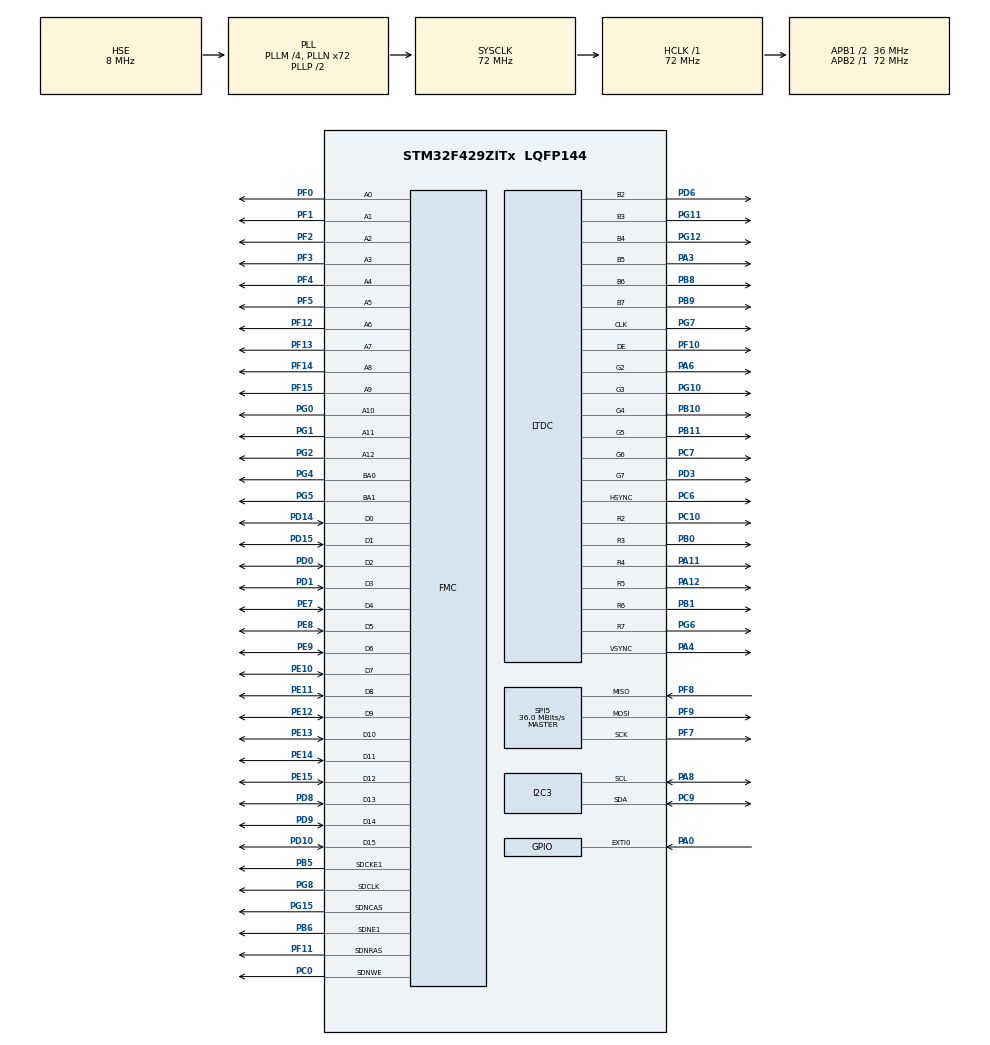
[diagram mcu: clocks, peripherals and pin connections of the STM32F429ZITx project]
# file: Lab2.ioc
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FREERTOS.INCLUDE_vTaskDelayUntil=1
FREERTOS.Queues01=myQueue01,50,uint8_t,0,Dynamic,NULL,NULL
FREERTOS.Tasks01=defaultTask,0,128,StartDefaultTask,Default,NULL,Dynamic,NULL,NULL
FREERTOS.configUSE_NEWLIB_REENTRANT=1
Mcu.Family=STM32F4
Mcu.Name=STM32F429ZITx
Mcu.Package=LQFP144
NVIC.EXTI0_IRQn=true\:5\:0\:false\:false\:true\:false\:true\:true\:true
NVIC.PriorityGroup=NVIC_PRIORITYGROUP_4
NVIC.TIM1_UP_TIM10_IRQn=true\:15\:0\:false\:false\:true\:false\:false\:true\:true
NVIC.TimeBase=TIM1_UP_TIM10_IRQn
NVIC.TimeBaseIP=TIM1
PA0/WKUP.Signal=GPXTI0
PA11.Mode=RGB666
PA11.Signal=LTDC_R4
PA12.Mode=RGB666
PA12.Signal=LTDC_R5
PA13.Mode=Serial_Wire
PA13.Signal=SYS_JTMS-SWDIO
PA14.Mode=Serial_Wire
PA14.Signal=SYS_JTCK-SWCLK
PA3.Mode=RGB666
PA3.Signal=LTDC_B5
PA4.Mode=RGB666
PA4.Signal=LTDC_VSYNC
PA6.Mode=RGB666
PA6.Signal=LTDC_G2
PA8.Mode=I2C
PA8.Signal=I2C3_SCL
PB0.Mode=RGB666
PB0.Signal=LTDC_R3
PB1.Mode=RGB666
PB1.Signal=LTDC_R6
PB10.Mode=RGB666
PB10.Signal=LTDC_G4
PB11.Mode=RGB666
PB11.Signal=LTDC_G5
PB5.Mode=SdramChipSelect2_1
PB5.Signal=FMC_SDCKE1
PB6.Mode=SdramChipSelect2_1
PB6.Signal=FMC_SDNE1
PB8.Mode=RGB666
PB8.Signal=LTDC_B6
PB9.Mode=RGB666
PB9.Signal=LTDC_B7
PC0.Signal=FMC_SDNWE
PC10.Mode=RGB666
PC10.Signal=LTDC_R2
PC6.Mode=RGB666
PC6.Signal=LTDC_HSYNC
PC7.Mode=RGB666
PC7.Signal=LTDC_G6
PC9.Mode=I2C
PC9.Signal=I2C3_SDA
PD0.Signal=FMC_D2_DA2
PD1.Signal=FMC_D3_DA3
PD10.Signal=FMC_D15_DA15
PD14.Signal=FMC_D0_DA0
PD15.Signal=FMC_D1_DA1
PD3.Mode=RGB666
PD3.Signal=LTDC_G7
PD6.Mode=RGB666
PD6.Signal=LTDC_B2
PD8.Signal=FMC_D13_DA13
PD9.Signal=FMC_D14_DA14
PE10.Signal=FMC_D7_DA7
PE11.Signal=FMC_D8_DA8
PE12.Signal=FMC_D9_DA9
PE13.Signal=FMC_D10_DA10
PE14.Signal=FMC_D11_DA11
PE15.Signal=FMC_D12_DA12
PE7.Signal=FMC_D4_DA4
PE8.Signal=FMC_D5_DA5
PE9.Signal=FMC_D6_DA6
PF0.Signal=FMC_A0
PF1.Signal=FMC_A1
PF10.Mode=RGB666
PF10.Signal=LTDC_DE
PF11.Signal=FMC_SDNRAS
PF12.Signal=FMC_A6
PF13.Signal=FMC_A7
PF14.Signal=FMC_A8
PF15.Signal=FMC_A9
PF2.Signal=FMC_A2
PF3.Signal=FMC_A3
PF4.Signal=FMC_A4
PF5.Signal=FMC_A5
PF7.Mode=Full_Duplex_Master
PF7.Signal=SPI5_SCK
PF8.Mode=Full_Duplex_Master
PF8.Signal=SPI5_MISO
PF9.Mode=Full_Duplex_Master
PF9.Signal=SPI5_MOSI
PG0.Signal=FMC_A10
PG1.Signal=FMC_A11
PG10.Mode=RGB666
PG10.Signal=LTDC_G3
PG11.Mode=RGB666
PG11.Signal=LTDC_B3
PG12.Mode=RGB666
PG12.Signal=LTDC_B4
PG15.Signal=FMC_SDNCAS
PG2.Signal=FMC_A12
PG4.Signal=FMC_A14_BA0
PG5.Signal=FMC_A15_BA1
PG6.Mode=RGB666
PG6.Signal=LTDC_R7
PG7.Mode=RGB666
PG7.Signal=LTDC_CLK
PG8.Signal=FMC_SDCLK
PH0/OSC_IN.Mode=HSE-External-Oscillator
PH0/OSC_IN.Signal=RCC_OSC_IN
PH1/OSC_OUT.Mode=HSE-External-Oscillator
PH1/OSC_OUT.Signal=RCC_OSC_OUT
ProjectManager.HeapSize=0x200
ProjectManager.StackSize=0x400
ProjectManager.TargetToolchain=STM32CubeIDE
RCC.48MHZClocksFreq_Value=48000000
RCC.AHBFreq_Value=72000000
RCC.APB1CLKDivider=RCC_HCLK_DIV2
RCC.APB1Freq_Value=36000000
RCC.APB1TimFreq_Value=72000000
RCC.APB2Freq_Value=72000000
RCC.APB2TimFreq_Value=72000000
RCC.CortexFreq_Value=72000000
RCC.HCLKFreq_Value=72000000
RCC.HSE_VALUE=8000000
RCC.HSI_VALUE=16000000
RCC.LSE_VALUE=32768
RCC.PLLM=4
RCC.PLLN=72
RCC.PLLQ=3
RCC.PLLSAIDivR=RCC_PLLSAIDIVR_4
RCC.PLLSAIN=50
RCC.PLLSAIR=5
RCC.PLLSourceVirtual=RCC_PLLSOURCE_HSE
RCC.SYSCLKFreq_VALUE=72000000
RCC.SYSCLKSource=RCC_SYSCLKSOURCE_PLLCLK
RCC.VCOOutputFreq_Value=144000000
SH.FMC_A0.0=FMC_A0,13b-sda1
SH.FMC_A1.0=FMC_A1,13b-sda1
SH.FMC_A10.0=FMC_A10,13b-sda1
SH.FMC_A11.0=FMC_A11,13b-sda1
SH.FMC_A12.0=FMC_A12,13b-sda1
SH.FMC_A14_BA0.0=FMC_BA0,FourSdramBanks1
SH.FMC_A15_BA1.0=FMC_BA1,FourSdramBanks1
SH.FMC_A2.0=FMC_A2,13b-sda1
SH.FMC_A3.0=FMC_A3,13b-sda1
SH.FMC_A4.0=FMC_A4,13b-sda1
SH.FMC_A5.0=FMC_A5,13b-sda1
SH.FMC_A6.0=FMC_A6,13b-sda1
SH.FMC_A7.0=FMC_A7,13b-sda1
SH.FMC_A8.0=FMC_A8,13b-sda1
SH.FMC_A9.0=FMC_A9,13b-sda1
SH.FMC_D0_DA0.0=FMC_D0,sd-16b-d1
SH.FMC_D10_DA10.0=FMC_D10,sd-16b-d1
SH.FMC_D11_DA11.0=FMC_D11,sd-16b-d1
SH.FMC_D12_DA12.0=FMC_D12,sd-16b-d1
SH.FMC_D13_DA13.0=FMC_D13,sd-16b-d1
SH.FMC_D14_DA14.0=FMC_D14,sd-16b-d1
SH.FMC_D15_DA15.0=FMC_D15,sd-16b-d1
SH.FMC_D1_DA1.0=FMC_D1,sd-16b-d1
SH.FMC_D2_DA2.0=FMC_D2,sd-16b-d1
SH.FMC_D3_DA3.0=FMC_D3,sd-16b-d1
SH.FMC_D4_DA4.0=FMC_D4,sd-16b-d1
SH.FMC_D5_DA5.0=FMC_D5,sd-16b-d1
SH.FMC_D6_DA6.0=FMC_D6,sd-16b-d1
SH.FMC_D7_DA7.0=FMC_D7,sd-16b-d1
SH.FMC_D8_DA8.0=FMC_D8,sd-16b-d1
SH.FMC_D9_DA9.0=FMC_D9,sd-16b-d1
SH.FMC_SDCLK.0=FMC_SDCLK,13b-sda1
SH.FMC_SDNCAS.0=FMC_SDNCAS,13b-sda1
SH.FMC_SDNRAS.0=FMC_SDNRAS,13b-sda1
SH.FMC_SDNWE.0=FMC_SDNWE,13b-sda1
SPI5.CalculateBaudRate=36.0 MBits/s
SPI5.Direction=SPI_DIRECTION_2LINES
SPI5.Mode=SPI_MODE_MASTER
SPI5.VirtualType=VM_MASTER
VP_DMA2D_VS_DMA2D.Mode=DMA2D_Activate
VP_FREERTOS_VS_CMSIS_V1.Mode=CMSIS_V1
VP_RNG_VS_RNG.Mode=RNG_Activate
VP_SYS_VS_tim1.Mode=TIM1
board=STM32F429I-DISC1

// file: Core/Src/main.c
/* USER CODE BEGIN Header */
/**
 ******************************************************************************
 * @file           : main.c
 * @brief          : Main program body
 ******************************************************************************
 * @attention
 *
 * Copyright (c) 2025 STMicroelectronics.
 * All rights reserved.
 *
 * This software is licensed under terms that can be found in the LICENSE file
 * in the root directory of this software component.
 * If no LICENSE file comes with this software, it is provided AS-IS.
 *
 ******************************************************************************
 */
/* USER CODE END Header */
#include "main.h"
#include "cmsis_os.h"
#include "stm32f429i_discovery_lcd.h"
#include "stm32f429i_discovery.h"
#include "stdio.h"
#include "string.h"
#include "semphr.h"

DMA2D_HandleTypeDef hdma2d;

I2C_HandleTypeDef hi2c3;

LTDC_HandleTypeDef hltdc;

RNG_HandleTypeDef hrng;

SPI_HandleTypeDef hspi5;

SDRAM_HandleTypeDef hsdram1;

// osThreadId defaultTaskHandle;
// osMessageQId myQueue01Handle;
/* USER CODE BEGIN PV */
int flag = 0;
osThreadId pTaskHandle[2];
int pTaskArg[2] = { 0, 1 };
int pTaskPriority[2] = { 24, 25 };
const char pTaskName[2][3] = { "T0", "T1" };
osMessageQId myQueueHandle[2];
TaskHandle_t HPT_Handle;
TaskHandle_t MPT_Handle;
TaskHandle_t LPT_Handle;
SemaphoreHandle_t SimpleMutex;
SemaphoreHandle_t BinSemaphore;
SemaphoreHandle_t LcdMutex;
SemaphoreHandle_t LcdMutex2;
/* USER CODE END PV */

void SystemClock_Config(void);
static void MX_GPIO_Init(void);
static void MX_DMA2D_Init(void);
static void MX_FMC_Init(void);
static void MX_I2C3_Init(void);
static void MX_LTDC_Init(void);
static void MX_SPI5_Init(void);
static void MX_RNG_Init(void);
//void StartDefaultTask(void const * argument);

/* USER CODE BEGIN PFP */
void MyTask(void*);
void HPT_Task(void*);
void MPT_Task(void*);
void LPT_Task(void*);
/* USER CODE END PFP */

int main(void) {

	/* USER CODE BEGIN 1 */
	int i, j;
	char num[15];

	/*for (i = 0; i < 5; i++) {
			for (j = 0; j < 2; j++) {
				BSP_LCD_SetTextColor(LCD_COLOR_GREEN);
				BSP_LCD_SetBackColor(LCD_COLOR_GREEN);
				BSP_LCD_FillRect(20 + 165 * j, 10 + 60 * i, 40, 30);
				BSP_LCD_SetTextColor(LCD_COLOR_BLACK);
				BSP_LCD_DrawRect(20 + 165 * j, 10 + 60 * i, 40, 30);
				sprintf(num, "%d", i);
				BSP_LCD_DisplayStringAt(35 + 165 * j, 20 + 60 * i, (uint8_t*) num,
						LEFT_MODE);
			}
			// Add boxes for the lower-priority three tasks to indicate trying to enter CS
			if (i > 1) {
				BSP_LCD_SetTextColor(LCD_COLOR_GREEN);
				BSP_LCD_SetBackColor(LCD_COLOR_GREEN);
				BSP_LCD_FillRect(105, 10 + 60 * i, 40, 30);
				BSP_LCD_SetTextColor(LCD_COLOR_BLACK);
				BSP_LCD_DrawRect(105, 10 + 60 * i, 40, 30);
				sprintf(num, "%d", i);
				BSP_LCD_DisplayStringAt(118, 20 + 60 * i, (uint8_t*) num,
						LEFT_MODE);
			}
		}*/
	/* USER CODE END 1 */

	/* MCU Configuration--------------------------------------------------------*/

	/* Reset of all peripherals, Initializes the Flash interface and the Systick. */
	HAL_Init();

	/* Configure the system clock */
	SystemClock_Config();

	/* Initialize all configured peripherals */
	MX_GPIO_Init();
	MX_DMA2D_Init();
	MX_FMC_Init();
	MX_I2C3_Init();
	MX_LTDC_Init();
	MX_SPI5_Init();
	MX_RNG_Init();
	/* USER CODE BEGIN 2 */

	BSP_LCD_Init();
	BSP_LCD_LayerDefaultInit(1, LCD_FRAME_BUFFER); // Initialize layer 1
	BSP_LCD_SelectLayer(1); // Set layer 1 as the foreground layer
	BSP_LCD_Clear(LCD_COLOR_BLUE); // Clear LCD
	BSP_LCD_SetColorKeying(1, LCD_COLOR_WHITE);
	BSP_LCD_SetLayerVisible(1, DISABLE);
	BSP_LCD_LayerDefaultInit(0, LCD_FRAME_BUFFER + 0x130000); // Initialize layer 0
	BSP_LCD_SelectLayer(0); // Set layer 0 as foreground
	BSP_LCD_DisplayOn();
	BSP_LCD_Clear(LCD_COLOR_WHITE);
	BSP_LCD_SetBackColor(LCD_COLOR_WHITE);
	BSP_LCD_SetFont(&Font20);
	for (i = 0; i < 5; i++) {
		for (j = 0; j < 2; j++) {
			BSP_LCD_SetTextColor(LCD_COLOR_GREEN);
			BSP_LCD_SetBackColor(LCD_COLOR_GREEN);
			BSP_LCD_FillRect(20 + 165 * j, 10 + 60 * i, 40, 30);
			BSP_LCD_SetTextColor(LCD_COLOR_BLACK);
			BSP_LCD_DrawRect(20 + 165 * j, 10 + 60 * i, 40, 30);
			sprintf(num, "%d", i);
			BSP_LCD_DisplayStringAt(35 + 165 * j, 20 + 60 * i, (uint8_t*) num,
					LEFT_MODE);
		}
	}
	for (i = 5; i > 0; i--) {
		BSP_LCD_SetTextColor(LCD_COLOR_BLACK);
		BSP_LCD_SetBackColor(LCD_COLOR_WHITE);
		sprintf(num, "%d", i);
		BSP_LCD_DisplayStringAt(115, 50, (uint8_t*) num, LEFT_MODE);
		HAL_Delay(1000);
	}
	/* USER CODE END 2 */

	/* USER CODE BEGIN RTOS_MUTEX */
	SimpleMutex = xSemaphoreCreateMutex();
	if (SimpleMutex == NULL) {
		Error_Handler();
	}

	/* USER CODE END RTOS_MUTEX */

	/* USER CODE BEGIN RTOS_SEMAPHORES */
	BinSemaphore = xSemaphoreCreateBinary();
	if (BinSemaphore == NULL) {
		Error_Handler();
	}
	xSemaphoreGive(BinSemaphore); // change count to 1
	LcdMutex = xSemaphoreCreateMutex();
	if (LcdMutex == NULL) {
		Error_Handler();
	}

	LcdMutex2 = xSemaphoreCreateMutex();
	if (LcdMutex2 == NULL) {
		Error_Handler();
	}
	// create tasks
	xTaskCreate(HPT_Task, "HPT", 128, NULL, 23, &HPT_Handle);
	xTaskCreate(MPT_Task, "MPT", 128, NULL, 22, &MPT_Handle);
	xTaskCreate(LPT_Task, "LPT", 128, NULL, 21, &LPT_Handle);
	/* USER CODE END RTOS_SEMAPHORES */

	/* Create the queue(s) */
	/* definition and creation of myQueue01 */
	//osMessageQDef(myQueue01, 50, uint8_t);
	//myQueue01Handle = osMessageCreate(osMessageQ(myQueue01), NULL);

	/* Create the thread(s) */
	/* definition and creation of defaultTask */
	//osThreadDef(defaultTask, StartDefaultTask, osPriorityNormal, 0, 128);
	//defaultTaskHandle = osThreadCreate(osThread(defaultTask), NULL);
	/* USER CODE BEGIN RTOS_THREADS */
	for (i = 0; i < 2; i++) {
		if (xTaskCreate((TaskFunction_t) MyTask, pTaskName[i], (uint16_t) 256,
				&pTaskArg[i], pTaskPriority[i],
				(TaskHandle_t*) &pTaskHandle[i])!=pdPASS)
			return -1;
		if ((myQueueHandle[i] = xQueueCreate(10, 4)) == NULL)
			return -1;
	}

	/* USER CODE END RTOS_THREADS */

	/* Start scheduler */
	vTaskStartScheduler();
	//changed from oskernelstart to vTaskStartScheduler as tasks were never running

	/* We should never get here as control is now taken by the scheduler */

	/* Infinite loop */
	while (1) {

	}

}

void SystemClock_Config(void) {
	RCC_OscInitTypeDef RCC_OscInitStruct = { 0 };
	RCC_ClkInitTypeDef RCC_ClkInitStruct = { 0 };

	/** Configure the main internal regulator output voltage
	 */
	__HAL_RCC_PWR_CLK_ENABLE();
	__HAL_PWR_VOLTAGESCALING_CONFIG(PWR_REGULATOR_VOLTAGE_SCALE3);

	/** Initializes the RCC Oscillators according to the specified parameters
	 * in the RCC_OscInitTypeDef structure.
	 */
	RCC_OscInitStruct.OscillatorType = RCC_OSCILLATORTYPE_HSE;
	RCC_OscInitStruct.HSEState = RCC_HSE_ON;
	RCC_OscInitStruct.PLL.PLLState = RCC_PLL_ON;
	RCC_OscInitStruct.PLL.PLLSource = RCC_PLLSOURCE_HSE;
	RCC_OscInitStruct.PLL.PLLM = 4;
	RCC_OscInitStruct.PLL.PLLN = 72;
	RCC_OscInitStruct.PLL.PLLP = RCC_PLLP_DIV2;
	RCC_OscInitStruct.PLL.PLLQ = 3;
	if (HAL_RCC_OscConfig(&RCC_OscInitStruct) != HAL_OK) {
		Error_Handler();
	}

	/** Initializes the CPU, AHB and APB buses clocks
	 */
	RCC_ClkInitStruct.ClockType = RCC_CLOCKTYPE_HCLK | RCC_CLOCKTYPE_SYSCLK
			| RCC_CLOCKTYPE_PCLK1 | RCC_CLOCKTYPE_PCLK2;
	RCC_ClkInitStruct.SYSCLKSource = RCC_SYSCLKSOURCE_PLLCLK;
	RCC_ClkInitStruct.AHBCLKDivider = RCC_SYSCLK_DIV1;
	RCC_ClkInitStruct.APB1CLKDivider = RCC_HCLK_DIV2;
	RCC_ClkInitStruct.APB2CLKDivider = RCC_HCLK_DIV1;

	if (HAL_RCC_ClockConfig(&RCC_ClkInitStruct, FLASH_LATENCY_2) != HAL_OK) {
		Error_Handler();
	}
}

static void MX_DMA2D_Init(void) {

	hdma2d.Instance = DMA2D;
	hdma2d.Init.Mode = DMA2D_M2M;
	hdma2d.Init.ColorMode = DMA2D_OUTPUT_ARGB8888;
	hdma2d.Init.OutputOffset = 0;
	hdma2d.LayerCfg[1].InputOffset = 0;
	hdma2d.LayerCfg[1].InputColorMode = DMA2D_INPUT_ARGB8888;
	hdma2d.LayerCfg[1].AlphaMode = DMA2D_NO_MODIF_ALPHA;
	hdma2d.LayerCfg[1].InputAlpha = 0;
	if (HAL_DMA2D_Init(&hdma2d) != HAL_OK) {
		Error_Handler();
	}
	if (HAL_DMA2D_ConfigLayer(&hdma2d, 1) != HAL_OK) {
		Error_Handler();
	}

}

static void MX_I2C3_Init(void) {

	hi2c3.Instance = I2C3;
	hi2c3.Init.ClockSpeed = 100000;
	hi2c3.Init.DutyCycle = I2C_DUTYCYCLE_2;
	hi2c3.Init.OwnAddress1 = 0;
	hi2c3.Init.AddressingMode = I2C_ADDRESSINGMODE_7BIT;
	hi2c3.Init.DualAddressMode = I2C_DUALADDRESS_DISABLE;
	hi2c3.Init.OwnAddress2 = 0;
	hi2c3.Init.GeneralCallMode = I2C_GENERALCALL_DISABLE;
	hi2c3.Init.NoStretchMode = I2C_NOSTRETCH_DISABLE;
	if (HAL_I2C_Init(&hi2c3) != HAL_OK) {
		Error_Handler();
	}

	/** Configure Analogue filter
	 */
	if (HAL_I2CEx_ConfigAnalogFilter(&hi2c3, I2C_ANALOGFILTER_ENABLE)
			!= HAL_OK) {
		Error_Handler();
	}

	/** Configure Digital filter
	 */
	if (HAL_I2CEx_ConfigDigitalFilter(&hi2c3, 0) != HAL_OK) {
		Error_Handler();
	}

}

static void MX_LTDC_Init(void) {

	LTDC_LayerCfgTypeDef pLayerCfg = { 0 };
	LTDC_LayerCfgTypeDef pLayerCfg1 = { 0 };

	hltdc.Instance = LTDC;
	hltdc.Init.HSPolarity = LTDC_HSPOLARITY_AL;
	hltdc.Init.VSPolarity = LTDC_VSPOLARITY_AL;
	hltdc.Init.DEPolarity = LTDC_DEPOLARITY_AL;
	hltdc.Init.PCPolarity = LTDC_PCPOLARITY_IPC;
	hltdc.Init.HorizontalSync = 7;
	hltdc.Init.VerticalSync = 3;
	hltdc.Init.AccumulatedHBP = 14;
	hltdc.Init.AccumulatedVBP = 5;
	hltdc.Init.AccumulatedActiveW = 654;
	hltdc.Init.AccumulatedActiveH = 485;
	hltdc.Init.TotalWidth = 660;
	hltdc.Init.TotalHeigh = 487;
	hltdc.Init.Backcolor.Blue = 0;
	hltdc.Init.Backcolor.Green = 0;
	hltdc.Init.Backcolor.Red = 0;
	if (HAL_LTDC_Init(&hltdc) != HAL_OK) {
		Error_Handler();
	}
	pLayerCfg.WindowX0 = 0;
	pLayerCfg.WindowX1 = 0;
	pLayerCfg.WindowY0 = 0;
	pLayerCfg.WindowY1 = 0;
	pLayerCfg.PixelFormat = LTDC_PIXEL_FORMAT_ARGB8888;
	pLayerCfg.Alpha = 0;
	pLayerCfg.Alpha0 = 0;
	pLayerCfg.BlendingFactor1 = LTDC_BLENDING_FACTOR1_CA;
	pLayerCfg.BlendingFactor2 = LTDC_BLENDING_FACTOR2_CA;
	pLayerCfg.FBStartAdress = 0;
	pLayerCfg.ImageWidth = 0;
	pLayerCfg.ImageHeight = 0;
	pLayerCfg.Backcolor.Blue = 0;
	pLayerCfg.Backcolor.Green = 0;
	pLayerCfg.Backcolor.Red = 0;
	if (HAL_LTDC_ConfigLayer(&hltdc, &pLayerCfg, 0) != HAL_OK) {
		Error_Handler();
	}
	pLayerCfg1.WindowX0 = 0;
	pLayerCfg1.WindowX1 = 0;
	pLayerCfg1.WindowY0 = 0;
	pLayerCfg1.WindowY1 = 0;
	pLayerCfg1.PixelFormat = LTDC_PIXEL_FORMAT_ARGB8888;
	pLayerCfg1.Alpha = 0;
	pLayerCfg1.Alpha0 = 0;
	pLayerCfg1.BlendingFactor1 = LTDC_BLENDING_FACTOR1_CA;
	pLayerCfg1.BlendingFactor2 = LTDC_BLENDING_FACTOR2_CA;
	pLayerCfg1.FBStartAdress = 0;
	pLayerCfg1.ImageWidth = 0;
	pLayerCfg1.ImageHeight = 0;
	pLayerCfg1.Backcolor.Blue = 0;
	pLayerCfg1.Backcolor.Green = 0;
	pLayerCfg1.Backcolor.Red = 0;
	if (HAL_LTDC_ConfigLayer(&hltdc, &pLayerCfg1, 1) != HAL_OK) {
		Error_Handler();
	}

}

static void MX_RNG_Init(void) {

	hrng.Instance = RNG;
	if (HAL_RNG_Init(&hrng) != HAL_OK) {
		Error_Handler();
	}

}

static void MX_SPI5_Init(void) {

	/* SPI5 parameter configuration*/
	hspi5.Instance = SPI5;
	hspi5.Init.Mode = SPI_MODE_MASTER;
	hspi5.Init.Direction = SPI_DIRECTION_2LINES;
	hspi5.Init.DataSize = SPI_DATASIZE_8BIT;
	hspi5.Init.CLKPolarity = SPI_POLARITY_LOW;
	hspi5.Init.CLKPhase = SPI_PHASE_1EDGE;
	hspi5.Init.NSS = SPI_NSS_SOFT;
	hspi5.Init.BaudRatePrescaler = SPI_BAUDRATEPRESCALER_2;
	hspi5.Init.FirstBit = SPI_FIRSTBIT_MSB;
	hspi5.Init.TIMode = SPI_TIMODE_DISABLE;
	hspi5.Init.CRCCalculation = SPI_CRCCALCULATION_DISABLE;
	hspi5.Init.CRCPolynomial = 10;
	if (HAL_SPI_Init(&hspi5) != HAL_OK) {
		Error_Handler();
	}

}

/* FMC initialization function */
static void MX_FMC_Init(void) {

	FMC_SDRAM_TimingTypeDef SdramTiming = { 0 };

	/** Perform the SDRAM1 memory initialization sequence
	 */
	hsdram1.Instance = FMC_SDRAM_DEVICE;
	/* hsdram1.Init */
	hsdram1.Init.SDBank = FMC_SDRAM_BANK2;
	hsdram1.Init.ColumnBitsNumber = FMC_SDRAM_COLUMN_BITS_NUM_8;
	hsdram1.Init.RowBitsNumber = FMC_SDRAM_ROW_BITS_NUM_13;
	hsdram1.Init.MemoryDataWidth = FMC_SDRAM_MEM_BUS_WIDTH_16;
	hsdram1.Init.InternalBankNumber = FMC_SDRAM_INTERN_BANKS_NUM_4;
	hsdram1.Init.CASLatency = FMC_SDRAM_CAS_LATENCY_1;
	hsdram1.Init.WriteProtection = FMC_SDRAM_WRITE_PROTECTION_DISABLE;
	hsdram1.Init.SDClockPeriod = FMC_SDRAM_CLOCK_DISABLE;
	hsdram1.Init.ReadBurst = FMC_SDRAM_RBURST_DISABLE;
	hsdram1.Init.ReadPipeDelay = FMC_SDRAM_RPIPE_DELAY_0;
	/* SdramTiming */
	SdramTiming.LoadToActiveDelay = 16;
	SdramTiming.ExitSelfRefreshDelay = 16;
	SdramTiming.SelfRefreshTime = 16;
	SdramTiming.RowCycleDelay = 16;
	SdramTiming.WriteRecoveryTime = 16;
	SdramTiming.RPDelay = 16;
	SdramTiming.RCDDelay = 16;

	if (HAL_SDRAM_Init(&hsdram1, &SdramTiming) != HAL_OK) {
		Error_Handler();
	}

}

static void MX_GPIO_Init(void) {
	GPIO_InitTypeDef GPIO_InitStruct = { 0 };

	/* GPIO Ports Clock Enable */
	__HAL_RCC_GPIOF_CLK_ENABLE();
	__HAL_RCC_GPIOH_CLK_ENABLE();
	__HAL_RCC_GPIOC_CLK_ENABLE();
	__HAL_RCC_GPIOA_CLK_ENABLE();
	__HAL_RCC_GPIOB_CLK_ENABLE();
	__HAL_RCC_GPIOG_CLK_ENABLE();
	__HAL_RCC_GPIOE_CLK_ENABLE();
	__HAL_RCC_GPIOD_CLK_ENABLE();

	/*Configure GPIO pin : PA0 */
	GPIO_InitStruct.Pin = GPIO_PIN_0;
	GPIO_InitStruct.Mode = GPIO_MODE_IT_RISING;
	GPIO_InitStruct.Pull = GPIO_NOPULL;
	HAL_GPIO_Init(GPIOA, &GPIO_InitStruct);

	/* EXTI interrupt init*/
	HAL_NVIC_SetPriority(EXTI0_IRQn, 5, 0);
	HAL_NVIC_EnableIRQ(EXTI0_IRQn);

}

/* USER CODE BEGIN 4 */
void HAL_GPIO_EXTI_Callback(uint16_t GPIO_Pin) {
	if (GPIO_Pin == GPIO_PIN_0) {
		flag = 1;
		uint32_t x;
		if (HAL_RNG_GenerateRandomNumber(&hrng, (uint32_t*) &x) != HAL_OK) {
			/* Report random number generation error */
			Error_Handler();
		}
		x = x % 2;
		BaseType_t btt = pdFALSE;
		//initializing basetype_t for xQueueSendToBAckFromISR
//			BSP_LCD_SetTextColor(LCD_COLOR_BLACK);
//			BSP_LCD_SetBackColor(LCD_COLOR_WHITE);
//			sprintf(num, "RNG:%ld", x);
//			BSP_LCD_DisplayStringAt(80, 50, (uint8_t*) num, LEFT_MODE);
		if (myQueueHandle[x] != 0) {
			//remove ticks
			//replacement for old version of xqueuesendtoback
			if (xQueueSendToBackFromISR(myQueueHandle[x], (void* ) &x, &btt)) {

			}
		}
		portYIELD_FROM_ISR(btt);
		//for making higher priority tasks immediately run

	}
}

void MyTask(void *arg) {
	int i = (int) *((int*) arg);
	uint32_t x;
	char num[15];
	int right_red = 0;
	BSP_LCD_SetTextColor(LCD_COLOR_BLACK);
	BSP_LCD_SetBackColor(LCD_COLOR_WHITE);
	//sprintf(num, "RNG:%ld", x);
	BSP_LCD_DisplayStringAt(80, 50, (uint8_t*) num, LEFT_MODE);

	TickType_t xLastWakeTime;
	// Define the desired period (e.g., 100ms)
	const TickType_t xPeriod = pdMS_TO_TICKS(100); // Converts milliseconds to ticks
	// 2. Initialize xLastWakeTime with the current tick count
	xLastWakeTime = xTaskGetTickCount();
	//amount of ticks that occurred since the scheduler started, current tick count
	for (;;) {

		BSP_LCD_SetTextColor(LCD_COLOR_RED); // set left button to red while working
		BSP_LCD_SetBackColor(LCD_COLOR_RED);
		//BSP_LCD_FillRect(20, 10 + 60 * i, 40, 30);
		BSP_LCD_SetTextColor(LCD_COLOR_BLACK);
		BSP_LCD_DrawRect(20, 10 + 60 * i, 40, 30);
		sprintf(num, "%d", i);
		BSP_LCD_DisplayStringAt(35, 20 + 60 * i, (uint8_t*) num, LEFT_MODE);

		vTaskDelayUntil(&xLastWakeTime, xPeriod);
		//periodic timing
		if (xQueueReceive(myQueueHandle[i], &x, 0) == pdPASS) {
			//makes the task not quarrel with lcd

			if (x == i) {
				BSP_LCD_SetTextColor(LCD_COLOR_BLACK);
				BSP_LCD_SetBackColor(LCD_COLOR_WHITE);
				sprintf(num, "RNG:%ld", x);
				BSP_LCD_DisplayStringAt(80, 50, (uint8_t*) num, LEFT_MODE);
				// remove message and toggle color of right RED/GREEN button
				if (right_red) {
					BSP_LCD_SetTextColor(LCD_COLOR_GREEN);
					BSP_LCD_SetBackColor(LCD_COLOR_GREEN);
					right_red = 0;
				} else {
					BSP_LCD_SetTextColor(LCD_COLOR_RED);
					BSP_LCD_SetBackColor(LCD_COLOR_RED);
					right_red = 1;
				}
			} else {

			}
			//osDelay(500);
			BSP_LCD_SetTextColor(LCD_COLOR_GREEN);
			BSP_LCD_SetBackColor(LCD_COLOR_GREEN);
			BSP_LCD_FillRect(20, 10 + 60 * i, 40, 30);
			BSP_LCD_SetTextColor(LCD_COLOR_BLACK);
			BSP_LCD_DrawRect(20, 10 + 60 * i, 40, 30);
			sprintf(num, "%d", i);
			BSP_LCD_DisplayStringAt(35, 20 + 60 * i, (uint8_t*) num, LEFT_MODE);
			//osDelay(500);
			//commenting out delays for faster response time
		}
	}
}
/* USER CODE END 4 */

void StartDefaultTask(void const *argument) {
	for (;;) {
		osDelay(1);
	}
}

void HAL_TIM_PeriodElapsedCallback(TIM_HandleTypeDef *htim) {
	if (htim->Instance == TIM1) {
		HAL_IncTick();
	}
}

void Error_Handler(void) {
	__disable_irq();
	while (1) {
	}
}

void HPT_Task(void *argument) {
	int i;
	char num[15];
	TickType_t xLastWakeTime;
	const TickType_t xPeriod = pdMS_TO_TICKS(2000); // Period = super slow 2 seconds
	xLastWakeTime = xTaskGetTickCount();
	while (1) {
		vTaskDelay(pdMS_TO_TICKS(400)); // sleep for 200 ms
// Two units of local work
		int row = 0; // for HPT
		int y = 130 + 60 * row;
//determining the y position as all boxes draw over each other
		for (i = 1; i <= 2; i++) {
			BSP_LCD_SetTextColor(LCD_COLOR_RED);
			BSP_LCD_SetBackColor(LCD_COLOR_RED);
			BSP_LCD_FillRect(20, y, 40, 30);
			BSP_LCD_SetTextColor(LCD_COLOR_BLACK);
			BSP_LCD_DrawRect(20, y, 40, 30);
			sprintf(num, "2");
			BSP_LCD_DisplayStringAt(35, 140, (uint8_t*) num, LEFT_MODE);
			vTaskDelay(pdMS_TO_TICKS(100)); // sleep for 100 ms
			BSP_LCD_SetTextColor(LCD_COLOR_GREEN);
			BSP_LCD_SetBackColor(LCD_COLOR_GREEN);
			BSP_LCD_FillRect(20, y, 40, 30);
			BSP_LCD_SetTextColor(LCD_COLOR_BLACK);
			BSP_LCD_DrawRect(20, y, 40, 30);
			sprintf(num, "2");
			BSP_LCD_DisplayStringAt(35, y, (uint8_t*) num, LEFT_MODE);
			vTaskDelay(pdMS_TO_TICKS(100)); // sleep for 100 ms
		}
// Try to obtain mutex semaphore
		BSP_LCD_SetTextColor(LCD_COLOR_RED);
		BSP_LCD_SetBackColor(LCD_COLOR_RED);
		BSP_LCD_FillRect(105, y, 40, 30);
		BSP_LCD_SetTextColor(LCD_COLOR_BLACK);
		BSP_LCD_DrawRect(105, y, 40, 30); // 10+60i = 130, j=20, 105, 185
		sprintf(num, "P");
		BSP_LCD_DisplayStringAt(120, y, (uint8_t*) num, LEFT_MODE);
		xSemaphoreTake(SimpleMutex, portMAX_DELAY);
		//xSemaphoreTake(LcdMutex2, portMAX_DELAY);
		//2nd lcdmutex to help stop flickering
// Enter critical section
		BSP_LCD_SetTextColor(LCD_COLOR_GREEN);
		BSP_LCD_SetBackColor(LCD_COLOR_GREEN);
		BSP_LCD_FillRect(105, y, 40, 30);
		BSP_LCD_SetTextColor(LCD_COLOR_BLACK);
		BSP_LCD_DrawRect(105, y, 40, 30); // 10+60i = 130, j=20, 105, 185
		sprintf(num, "2");
		BSP_LCD_DisplayStringAt(120, 140, (uint8_t*) num, LEFT_MODE);
		BSP_LCD_SetTextColor(LCD_COLOR_RED);
		BSP_LCD_SetBackColor(LCD_COLOR_RED);
		BSP_LCD_FillRect(185, y, 40, 30);
		BSP_LCD_SetTextColor(LCD_COLOR_BLACK);
		BSP_LCD_DrawRect(185, y, 40, 30); // 10+60i = 130, j=20, 105, 185
		sprintf(num, "C");
		BSP_LCD_DisplayStringAt(200, y, (uint8_t*) num, LEFT_MODE);
		vTaskDelay(pdMS_TO_TICKS(300)); // in CS for 300 ms
		xSemaphoreGive(SimpleMutex);
		//xSemaphoreGive(LcdMutex2);
// Leave critical section
		BSP_LCD_SetTextColor(LCD_COLOR_GREEN);
		BSP_LCD_SetBackColor(LCD_COLOR_GREEN);
		BSP_LCD_FillRect(185, y, 40, 30);
		BSP_LCD_SetTextColor(LCD_COLOR_BLACK);
		BSP_LCD_DrawRect(185, y, 40, 30);
		sprintf(num, "2");
		BSP_LCD_DisplayStringAt(200, y, (uint8_t*) num, LEFT_MODE);
// Wait for period to expire
		vTaskDelayUntil(&xLastWakeTime, xPeriod);
	}
}

void MPT_Task(void *argument) {
	int i;
	char num[15];
	TickType_t xLastWakeTime;
	const TickType_t xPeriod = pdMS_TO_TICKS(1000); // Period = super slow 2 seconds
	xLastWakeTime = xTaskGetTickCount();
	while (1) {
		vTaskDelay(pdMS_TO_TICKS(200)); // sleep for 200 ms
// Two units of local work
		int row = 1; // for MPT
		int y = 130 + 60 * row;
//determining the y position as all boxes draw over each other
		for (i = 1; i <= 10; i++) {
			BSP_LCD_SetTextColor(LCD_COLOR_RED);
			BSP_LCD_SetBackColor(LCD_COLOR_RED);
			BSP_LCD_FillRect(20, y, 40, 30);
			BSP_LCD_SetTextColor(LCD_COLOR_BLACK);
			BSP_LCD_DrawRect(20, y, 40, 30);
			sprintf(num, "2");
			BSP_LCD_DisplayStringAt(35, y, (uint8_t*) num, LEFT_MODE);
			vTaskDelay(pdMS_TO_TICKS(100)); // sleep for 100 ms
			BSP_LCD_SetTextColor(LCD_COLOR_GREEN);
			BSP_LCD_SetBackColor(LCD_COLOR_GREEN);
			BSP_LCD_FillRect(20, y, 40, 30);
			BSP_LCD_SetTextColor(LCD_COLOR_BLACK);
			BSP_LCD_DrawRect(20, y, 40, 30);
			sprintf(num, "2");
			BSP_LCD_DisplayStringAt(35, y, (uint8_t*) num, LEFT_MODE);
			vTaskDelay(pdMS_TO_TICKS(100)); // sleep for 100 ms
		}
// Try to obtain mutex semaphore
		BSP_LCD_SetTextColor(LCD_COLOR_RED);
		BSP_LCD_SetBackColor(LCD_COLOR_RED);
		BSP_LCD_FillRect(105, y, 40, 30);
		BSP_LCD_SetTextColor(LCD_COLOR_BLACK);
		BSP_LCD_DrawRect(105, y, 40, 30); // 10+60i = 130, j=20, 105, 185
		sprintf(num, "P");
		BSP_LCD_DisplayStringAt(120, y, (uint8_t*) num, LEFT_MODE);
		//xSemaphoreTake(SimpleMutex, portMAX_DELAY);
		//xSemaphoreTake(LcdMutex2, portMAX_DELAY);
// Enter critical section
		BSP_LCD_SetTextColor(LCD_COLOR_GREEN);
		BSP_LCD_SetBackColor(LCD_COLOR_GREEN);
		BSP_LCD_FillRect(105, y, 40, 30);
		BSP_LCD_SetTextColor(LCD_COLOR_BLACK);
		BSP_LCD_DrawRect(105, y, 40, 30); // 10+60i = 130, j=20, 105, 185
		sprintf(num, "2");
		BSP_LCD_DisplayStringAt(120, y, (uint8_t*) num, LEFT_MODE);
		BSP_LCD_SetTextColor(LCD_COLOR_RED);
		BSP_LCD_SetBackColor(LCD_COLOR_RED);
		BSP_LCD_FillRect(185, y, 40, 30);
		BSP_LCD_SetTextColor(LCD_COLOR_BLACK);
		BSP_LCD_DrawRect(185, y, 40, 30); // 10+60i = 130, j=20, 105, 185
		sprintf(num, "C");
		BSP_LCD_DisplayStringAt(200, y, (uint8_t*) num, LEFT_MODE);
		vTaskDelay(pdMS_TO_TICKS(300)); // in CS for 300 ms
		//xSemaphoreGive(SimpleMutex);
		//xSemaphoreGive(LcdMutex2);
// Leave critical section
		BSP_LCD_SetTextColor(LCD_COLOR_GREEN);
		BSP_LCD_SetBackColor(LCD_COLOR_GREEN);
		BSP_LCD_FillRect(185, y, 40, 30);
		BSP_LCD_SetTextColor(LCD_COLOR_BLACK);
		BSP_LCD_DrawRect(185, y, 40, 30);
		sprintf(num, "2");
		BSP_LCD_DisplayStringAt(200, y, (uint8_t*) num, LEFT_MODE);
// Wait for period to expire
		vTaskDelayUntil(&xLastWakeTime, xPeriod);
	}
}

void LPT_Task(void *argument) {
	int i;
	char num[15];
	TickType_t xLastWakeTime;
	const TickType_t xPeriod = pdMS_TO_TICKS(2000); // Period = super slow 2 seconds
	xLastWakeTime = xTaskGetTickCount();
	while (1) {
		vTaskDelay(pdMS_TO_TICKS(50)); // sleep for 200 ms
// Two units of local work
		int row = 2; // for LPT
		int y = 130 + 60 * row;
//determining the y position as all boxes draw over each other
		for (i=1; i<=10; i++) {
		vTaskDelay(pdMS_TO_TICKS(100)); // in CS for 1000 ms total
		xSemaphoreTake(LcdMutex, portMAX_DELAY);
		//xSemaphoreTake(LcdMutex2, portMAX_DELAY);
		sprintf(num, "PRIORITY: %ld", uxTaskPriorityGet(NULL));
		//changed l[t_handle to null since priotity number wasn't switching from 21, forever stuck on low priority
		BSP_LCD_SetTextColor(LCD_COLOR_BLACK);
		BSP_LCD_SetBackColor(LCD_COLOR_WHITE);
		BSP_LCD_DisplayStringAt(35,290,(uint8_t*) num, LEFT_MODE);
		xSemaphoreGive(LcdMutex);
		//xSemaphoreGive(LcdMutex2);
		//changing from simple to lcd didn't change the priority but the screen is a lot less flickery and you can see different and
		//clear changes. For example, priority box now changes to green sometimes and you can clearly notice the letters
		//replace boxes instead of quickly showing up and disappering
		}
// Try to obtain mutex semaphore
		BSP_LCD_SetTextColor(LCD_COLOR_RED);
		BSP_LCD_SetBackColor(LCD_COLOR_RED);
		BSP_LCD_FillRect(105, y, 40, 30);
		BSP_LCD_SetTextColor(LCD_COLOR_BLACK);
		BSP_LCD_DrawRect(105, y, 40, 30); // 10+60i = 130, j=20, 105, 185
		sprintf(num, "P");
		BSP_LCD_DisplayStringAt(120, y, (uint8_t*) num, LEFT_MODE);
		xSemaphoreTake(SimpleMutex, portMAX_DELAY);
		//xSemaphoreTake(LcdMutex2, portMAX_DELAY);
// Enter critical section
		BSP_LCD_SetTextColor(LCD_COLOR_GREEN);
		BSP_LCD_SetBackColor(LCD_COLOR_GREEN);
		BSP_LCD_FillRect(105, y, 40, 30);
		BSP_LCD_SetTextColor(LCD_COLOR_BLACK);
		BSP_LCD_DrawRect(105, y, 40, 30); // 10+60i = 130, j=20, 105, 185
		sprintf(num, "2");
		BSP_LCD_DisplayStringAt(120, y, (uint8_t*) num, LEFT_MODE);
		BSP_LCD_SetTextColor(LCD_COLOR_RED);
		BSP_LCD_SetBackColor(LCD_COLOR_RED);
		BSP_LCD_FillRect(185, y, 40, 30);
		BSP_LCD_SetTextColor(LCD_COLOR_BLACK);
		BSP_LCD_DrawRect(185, y, 40, 30); // 10+60i = 130, j=20, 105, 185
		sprintf(num, "C");
		BSP_LCD_DisplayStringAt(200, y, (uint8_t*) num, LEFT_MODE);
		//vTaskDelay(pdMS_TO_TICKS(300)); // in CS for 300 ms
		for (volatile uint32_t j = 0; j < 8000000; j++);
		xSemaphoreGive(SimpleMutex);
		//xSemaphoreGive(LcdMutex2);
// Leave critical section
		BSP_LCD_SetTextColor(LCD_COLOR_GREEN);
		BSP_LCD_SetBackColor(LCD_COLOR_GREEN);
		BSP_LCD_FillRect(185, y, 40, 30);
		BSP_LCD_SetTextColor(LCD_COLOR_BLACK);
		BSP_LCD_DrawRect(185, y, 40, 30);
		sprintf(num, "2");
		BSP_LCD_DisplayStringAt(200, y, (uint8_t*) num, LEFT_MODE);
// Wait for period to expire
		vTaskDelayUntil(&xLastWakeTime, xPeriod);
	}
}
